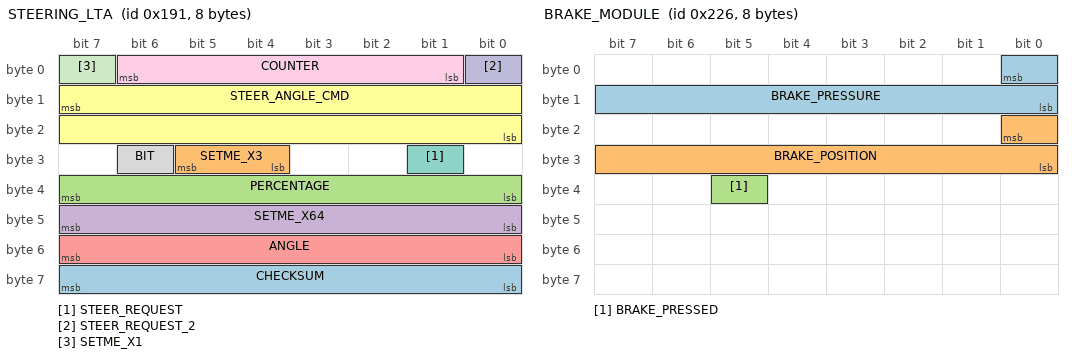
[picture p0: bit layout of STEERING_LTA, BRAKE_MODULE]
BO_ 401 STEERING_LTA: 8 XXX
 SG_ CHECKSUM : 63|8@0+ (1,0) [0|255] "" XXX
 SG_ SETME_X3 : 29|2@0+ (1,0) [0|3] "" XXX
 SG_ PERCENTAGE : 39|8@0+ (1,0) [0|255] "" XXX
 SG_ SETME_X64 : 47|8@0+ (1,0) [0|255] "" XXX
 SG_ ANGLE : 55|8@0- (0.5,0) [0|255] "" XXX
 SG_ STEER_ANGLE_CMD : 15|16@0- (0.0573,0) [-540|540] "" XXX
 SG_ STEER_REQUEST : 25|1@0+ (1,0) [0|1] "" XXX
 SG_ BIT : 30|1@0+ (1,0) [0|1] "" XXX
 SG_ COUNTER : 6|6@0+ (1,0) [0|255] "" XXX
 SG_ STEER_REQUEST_2 : 0|1@0+ (1,0) [0|1] "" XXX
 SG_ SETME_X1 : 7|1@0+ (1,0) [0|1] "" XXX

BO_ 550 BRAKE_MODULE: 8 XXX
 SG_ BRAKE_PRESSURE : 0|9@0+ (1,0) [0|511] "" XXX
 SG_ BRAKE_POSITION : 16|9@0+ (1,0) [0|511] "" XXX
 SG_ BRAKE_PRESSED : 37|1@0+ (1,0) [0|1] "" XXX

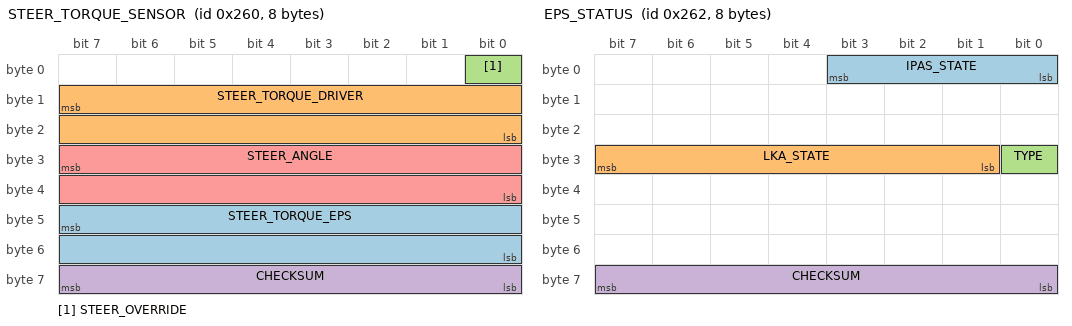
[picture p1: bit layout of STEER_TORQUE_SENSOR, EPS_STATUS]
BO_ 608 STEER_TORQUE_SENSOR: 8 XXX
 SG_ STEER_TORQUE_EPS : 47|16@0- (0.73,0) [-20000|20000] "" XXX
 SG_ STEER_TORQUE_DRIVER : 15|16@0- (1,0) [-32768|32767] "" XXX
 SG_ STEER_OVERRIDE : 0|1@0+ (1,0) [0|1] "" XXX
 SG_ CHECKSUM : 63|8@0+ (1,0) [0|255] "" XXX
 SG_ STEER_ANGLE : 31|16@0- (0.0573,0) [-500|500] "" XXX

BO_ 610 EPS_STATUS: 8 EPS
 SG_ IPAS_STATE : 3|4@0+ (1,0) [0|15] "" XXX
 SG_ LKA_STATE : 31|7@0+ (1,0) [0|127] "" XXX
 SG_ TYPE : 24|1@0+ (1,0) [0|1] "" XXX
 SG_ CHECKSUM : 63|8@0+ (1,0) [0|255] "" XXX

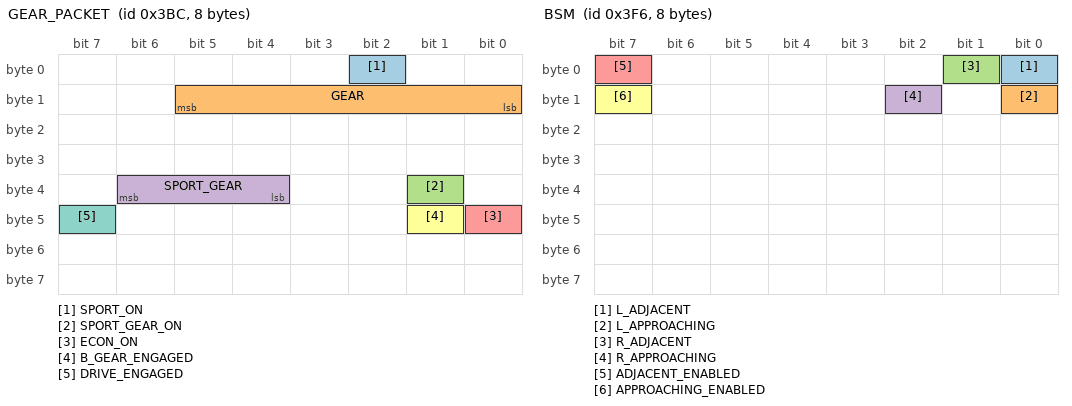
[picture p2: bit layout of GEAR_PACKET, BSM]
BO_ 956 GEAR_PACKET: 8 XXX
 SG_ SPORT_ON : 2|1@0+ (1,0) [0|1] "" XXX
 SG_ GEAR : 13|6@0+ (1,0) [0|63] "" XXX
 SG_ SPORT_GEAR_ON : 33|1@0+ (1,0) [0|1] "" XXX
 SG_ SPORT_GEAR : 38|3@0+ (1,0) [0|7] "" XXX
 SG_ ECON_ON : 40|1@0+ (1,0) [0|1] "" XXX
 SG_ B_GEAR_ENGAGED : 41|1@0+ (1,0) [0|1] "" XXX
 SG_ DRIVE_ENGAGED : 47|1@0+ (1,0) [0|1] "" XXX

BO_ 1014 BSM: 8 XXX
 SG_ L_ADJACENT : 0|1@0+ (1,0) [0|1] "" XXX
 SG_ L_APPROACHING : 8|1@0+ (1,0) [0|1] "" XXX
 SG_ R_ADJACENT : 1|1@0+ (1,0) [0|1] "" XXX
 SG_ R_APPROACHING : 10|1@0+ (1,0) [0|1] "" XXX
 SG_ ADJACENT_ENABLED : 7|1@0+ (1,0) [0|1] "" XXX
 SG_ APPROACHING_ENABLED : 15|1@0+ (1,0) [0|1] "" XXX

CM_ SG_ 550 BRAKE_PRESSURE "seems prop to pedal force";
CM_ SG_ 550 BRAKE_POSITION "seems proportional to pedal displacement, unclear the max value of 0x1c8";
CM_ SG_ 610 TYPE "seems 1 on Corolla, 0 on all others";
VAL_ 956 SPORT_ON 0 "off" 1 "on";
VAL_ 956 GEAR 0 "D" 1 "S" 8 "N" 16 "R" 32 "P";
VAL_ 956 SPORT_GEAR_ON 0 "off" 1 "on";
VAL_ 956 SPORT_GEAR 1 "S1" 2 "S2" 3 "S3" 4 "S4" 5 "S5" 6 "S6";
VAL_ 956 ECON_ON 0 "off" 1 "on";
VAL_ 956 B_GEAR_ENGAGED 0 "off" 1 "on";
VAL_ 956 DRIVE_ENGAGED 0 "off" 1 "on";
CM_ SG_ 1014 L_ADJACENT "vehicle adjacent left side of car. enabled above 10mph, regardless of ADJACENT_ENABLED or APPROACHING_ENABLED";
CM_ SG_ 1014 L_APPROACHING "vehicle approaching from left side of car. enabled above 10mph, regardless of ADJACENT_ENABLED or APPROACHING_ENABLED";
CM_ SG_ 1014 R_ADJACENT "vehicle adjacent right side of car. enabled above 10mph, regardless of ADJACENT_ENABLED or APPROACHING_ENABLED";
CM_ SG_ 1014 R_APPROACHING "vehicle approaching from right side of car. enabled above 10mph, regardless of ADJACENT_ENABLED or APPROACHING_ENABLED";
CM_ SG_ 1014 ADJACENT_ENABLED "when BSM is enabled in settings, this is on along with APPROACHING_ENABLED. this controls bsm alert visibility";
CM_ SG_ 1014 APPROACHING_ENABLED "when BSM is enabled in settings, this is on along with ADJACENT_ENABLED. this controls bsm alert visibility";
VAL_ 610 IPAS_STATE 5 "override" 3 "enabled" 1 "disabled";
VAL_ 610 LKA_STATE 25 "temporary_fault" 9 "temporary_fault2" 5 "active" 1 "standby";
